# RT584ZCM33 register map
Series: ARMv8-M Mainline; File version: 1.0
CPU: CM33 r0p0, little endian, MPU, no FPU, VTOR, 3 interrupt priority bits
Registers are 32-bit, read-write, reset 0x0 unless marked. A register's access mark holds for its fields unless they carry their own. Offsets are from the block's base; [hi:lo] are bit positions.

## Comm_Non-Secure — Comm Non-Secure Register block
Base 0x4001A000
Same registers: Comm_Secure 0x5001A000
0x00 COMM_DMA0_REG — dma ahb addr
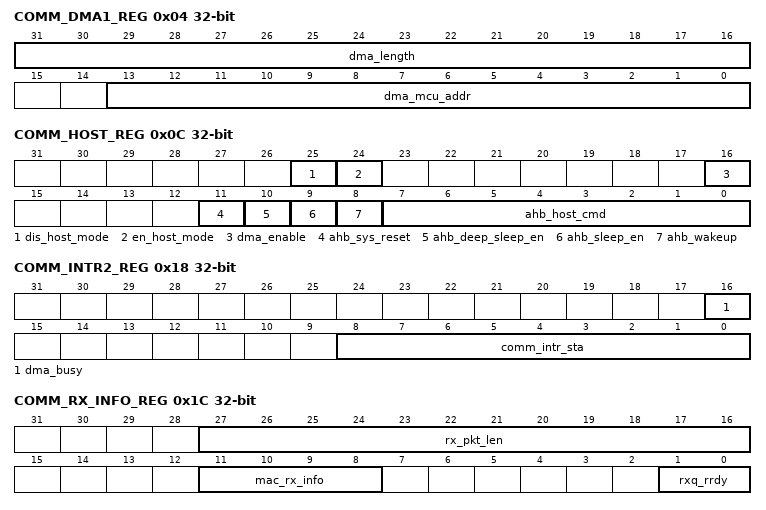
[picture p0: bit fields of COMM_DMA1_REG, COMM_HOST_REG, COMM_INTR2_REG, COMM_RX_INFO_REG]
0x04 COMM_DMA1_REG — comm dma1
  [31:16] dma_length — Data legnth to be transferred. It must be greater than 0 which is undefined.
  [13:0] dma_mcu_addr — If dma_type = 2'b00 , this indicates RXQ ID. If dma_type = 2'b01 , this indicates TXQ ID. If dma_type = 2'b1x , this indicates COMM Subsys mem address[15:2].
0x08 COMM_DMA2_REG — comm dma2
  [1:0] dma_type — DMA transfer type. The read or write is from the perspective of HOST CPU. 0: I/O read. 1: I/O write. 2: Memory read. 3: Memory write.
    0=B_0_to_1_ITEM0 (I/O read.); 1=B_0_to_1_ITEM1 (I/O write.); 2=B_0_to_1_ITEM2 (Memory read.); 3=B_0_to_1_ITEM3 (Memory write.)
0x0C COMM_HOST_REG wo — comm host
  [25] dis_host_mode — Write 1 to disable host mode
    0=B_25 (Write 1 to disable host mode)
  [24] en_host_mode — Write 1 to enable host mode
    0=B_24 (Write 1 to enable host mode)
  [16] dma_enable — Write 1 to start AHB DMA
    0=B_16 (Write 1 to start AHB DMA)
  [11] ahb_sys_reset — Write 1 to reset COMM Subsys
    0=B_11 (Write 1 to reset COMM Subsys)
  [10] ahb_deep_sleep_en — Write 1 to let COMM Subsys entering Deepsleep Mode
    0=B_10 (Write 1 to let COMM Subsys entering Deepsleep Mode)
  [9] ahb_sleep_en — Write 1 to let COMM Subsys entering Sleep Mode
    0=B_9 (Write 1 to let COMM Subsys entering Sleep Mode)
  [8] ahb_wakeup — Write 1 to wakeup COMM Subsys
    0=B_8 (Write 1 to wakeup COMM Subsys)
  [7:0] ahb_host_cmd — Write 1 to enable corresponding COMM Subsys host commands
    0=B_0_to_7 (Write 1 to enable corresponding COMM Subsys host commands)
0x10 COMM_INTR0_REG reset 0x20000 — comm intr0
  [8:0] comm_intr_en — Set the specific bit to high to enable corresponding interrupts from COMM Subsys. bit 0: MCU soft interrupt 0. bit 1: MCU soft interrupt 1. bit 2: MCU soft interrupt 2. bit 3: MCU soft interrupt 3. bit 4: MCU soft interrupt 4. bit 5: RX packet valid interrupt. bit 6: Data transfer error interrupt (reserved for debug only). bit 7: COMM Subsys RTC interrupt (reserved for debug only). bit 8: DMA done interrupt.
0x14 COMM_INTR1_REG wo — comm intr1
  [8:0] comm_intr_clr — Set the specific bit to high to clear corresponding interrupts from COMM Subsys. bit 0: MCU soft interrupt 0. bit 1: MCU soft interrupt 1. bit 2: MCU soft interrupt 2. bit 3: MCU soft interrupt 3. bit 4: MCU soft interrupt 4. bit 5: RX packet valid interrupt. bit 6: Data transfer error interrupt (reserved for debug only). bit 7: COMM Subsys RTC interrupt (reserved for debug only). bit 8: DMA done interrupt.
0x18 COMM_INTR2_REG ro — comm intr2
  [16] dma_busy — COMM Subsys DMA busy flag. 0: Idle 1: Busy
    0=B_16_ITEM0 (Idle); 1=B_16_ITEM1 (Busy)
  [8:0] comm_intr_sta — Interrupt status. bit 0: MCU soft interrupt 0. bit 1: MCU soft interrupt 1. bit 2: MCU soft interrupt 2. bit 3: MCU soft interrupt 3. bit 4: MCU soft interrupt 4. bit 5: RX packet valid interrupt. bit 6: Data transfer error interrupt (reserved for debug only). bit 7: COMM Subsys RTC interrupt (reserved for debug only). bit 8: DMA done interrupt.
0x1C COMM_RX_INFO_REG ro — comm rx info
  [27:16] rx_pkt_len — Indicate the data length in RxQ #0.
  [11:8] mac_rx_info — MAC RX information. [0] Packet length error [1] CRC error [2] MIC error [3] Buffer error
    0=B_8_to_11 (MAC RX information. [0] Packet length error [1] CRC error [2] MIC error [3] Buffer error)
  [1:0] rxq_rrdy — High to indicates the data is available in the corresponding RxQ. [0] is for RxQ #0 and [1] is for RxQ #1.
    0=B_0_to_1 (High to indicates the data is available in the corresponding RxQ. [0] is for RxQ #0 and [1] is for RxQ #1.)
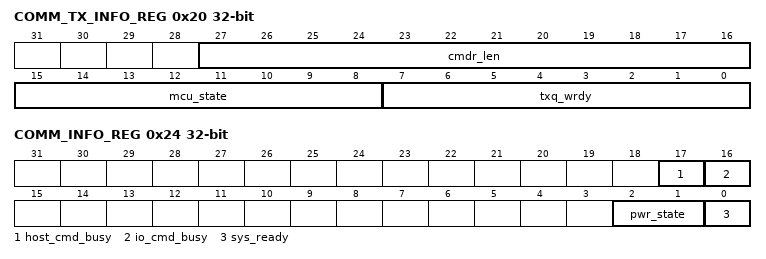
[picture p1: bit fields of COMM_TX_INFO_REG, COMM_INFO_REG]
0x20 COMM_TX_INFO_REG ro — comm tx info
  [27:16] cmdr_len — Indicate the data length of the command response in RxQ #1.
  [15:8] mcu_state — The MCU state defined by the firmware of COMM Subsys.
    0=B_8_to_15 (The MCU state defined by the firmware of COMM Subsys.)
  [7:0] txq_wrdy — High to indicates the corresponding TxQ is available. [0] is for TxQ #0, [1] is for TxQ #1, and so on.
    0=B_0_to_7 (High to indicates the corresponding TxQ is available. [0] is for TxQ #0, [1] is for TxQ #1, and so on.)
0x24 COMM_INFO_REG ro — comm info
  [17] host_cmd_busy — HOST command busy flag. 0: Idle 1: Busy
    0=B_17_ITEM0 (Idle); 1=B_17_ITEM1 (Busy)
  [16] io_cmd_busy — IO command busy flag. 0: Idle 1: Busy
    0=B_16_ITEM0 (Idle); 1=B_16_ITEM1 (Busy)
  [2:1] pwr_state — The power state of COMM Subsys. 0: Other transition states 1: Deep Sleep 2: Sleep 3: Normal
    0=B_1_to_2_ITEM0 (Other transition states); 1=B_1_to_2_ITEM1 (Deep Sleep); 2=B_1_to_2_ITEM2 (Sleep); 3=B_1_to_2_ITEM3 (Normal)
  [0] sys_ready — COMM Subsys status flag. 0: COMM Subsys is reseting and can't be accessed. 1: COMM Subsys is ready for access.
    0=B_0_ITEM0 (COMM Subsys is reseting and can't be accessed.); 1=B_0_ITEM1 (COMM Subsys is ready for access.)
0x28 COMM_DW_W_REG — The write data for dw_write.
0x2C COMM_DW_R_REG ro — The read data for dw_read. If dw_busy is 1 , this data is invalid.
0x30 COMM_RTC_SLOW_REG ro — The rtc_cnt_slow.
